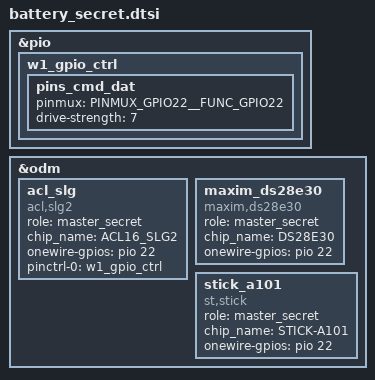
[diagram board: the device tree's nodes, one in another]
&pio {
    w1_gpio_ctrl: w1_gpio_ctrl {
        pins_cmd_dat {
            pinmux = <PINMUX_GPIO22__FUNC_GPIO22>;
            drive-strength = <7>;
        };
    };
};

&odm {
    acl_slg: acl_slg {
        compatible = "acl,slg2";
        role = "master_secret";
        chip_name = "ACL16_SLG2";
        //gpios = <&pio 17 0x00>;
        onewire-gpios = <&pio 22 0x00>;
        pinctrl-names = "default";
        pinctrl-0 = <&w1_gpio_ctrl>;
        status = "okay";
    };

    maxim_ds28e30: maxim_ds28e30 {
        compatible = "maxim,ds28e30";
        role = "master_secret";
        chip_name = "DS28E30";
        onewire-gpios = <&pio 22 0x00>;
        status = "okay";
    };

    stick_a101: stick_a101 {
        compatible = "st,stick";
        role = "master_secret";
        chip_name = "STICK-A101";
        onewire-gpios = <&pio 22 0x00>;
        status = "okay";
    };
};
